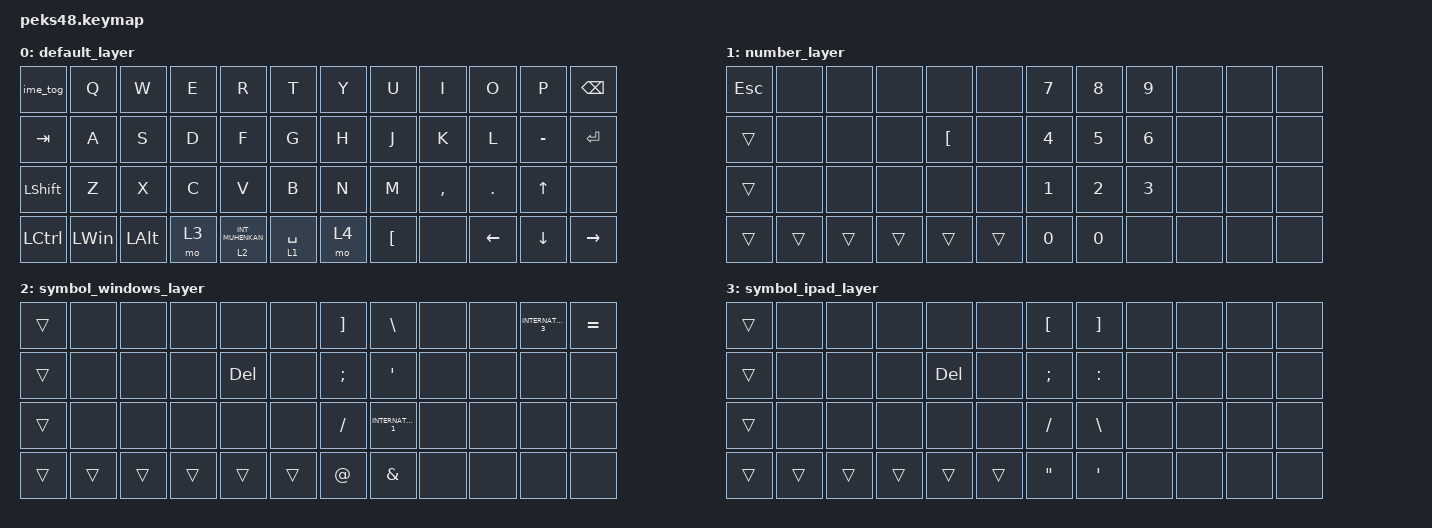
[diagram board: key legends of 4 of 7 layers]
#include <input/processors.dtsi>
#include <dt-bindings/zmk/input_transform.h>
#include <zephyr/dt-bindings/input/input-event-codes.h>
#include <behaviors.dtsi>
#include <dt-bindings/zmk/bt.h>
#include <dt-bindings/zmk/keys.h>
#include <dt-bindings/zmk/pointing.h>

// Conversion definition for using Japanese keyboard with OS settings

#define JP_DQUOTE       AT                // "
#define JP_AMPERSAND    CARET             // &
#define JP_QUOTE        AMPERSAND         // '
#define JP_EQUAL        UNDER             // =
#define JP_CARET        EQUAL             // ^
#define JP_YEN          0x89              // ¥
#define JP_PLUS         COLON             // +
#define JP_TILDE        PLUS              // ~
#define JP_PIPE         LS(0x89)          // |
#define JP_AT           LEFT_BRACKET      // @
#define JP_COLON        SINGLE_QUOTE      // :
#define JP_ASTERISK     DOUBLE_QUOTES     // *
#define JP_BACKQUOTE    LEFT_BRACE        // `
#define JP_UNDERSCORE   LS(0x87)          // _
#define JP_LBRACKET     RIGHT_BRACKET     // [
#define JP_RBRACKET     BACKSLASH         // ]
#define JP_LPAREN       ASTERISK          // (
#define JP_RPAREN       LEFT_PARENTHESIS  // )
#define JP_LBRACE       RIGHT_BRACE       // {
#define JP_RBRACE       PIPE              // }
#define JP_KANA         LANGUAGE_1        // かな
#define JP_EISU         LANGUAGE_2        // 英数
#define JP_HANZEN       GRAVE             // 半角/全角

&mt {
    flavor = "balanced";
    quick-tap-ms = <0>;
};

/ {
    macros {
        ime_tog: new_macro {
            compatible = "zmk,behavior-macro";
            #binding-cells = <0>;
            bindings =
                <&macro_press>,
                <&kp LALT>,
                <&macro_tap>,
                <&kp GRAVE>,
                <&macro_release>,
                <&kp LALT>;

            label = "NEW_MACRO";
        };
    };

    keymap {
        compatible = "zmk,keymap";

        default_layer {
            bindings = <
&ime_tog    &kp Q         &kp W         &kp E  &kp R               &kp T          &kp Y  &kp U             &kp I      &kp O           &kp P           &kp BACKSPACE
&kp TAB     &kp A         &kp S         &kp D  &kp F               &kp G          &kp H  &kp J             &kp K      &kp L           &kp MINUS       &kp ENTER
&kp LSHIFT  &kp Z         &kp X         &kp C  &kp V               &kp B          &kp N  &kp M             &kp COMMA  &kp DOT         &kp UP_ARROW    &none
&kp LCTRL   &kp LEFT_WIN  &kp LEFT_ALT  &mo 3  &lt 2 INT_MUHENKAN  &lt 1 SPACE    &mo 4  &kp LEFT_BRACKET  &none      &kp LEFT_ARROW  &kp DOWN_ARROW  &kp RIGHT_ARROW
            >;
        };

        number_layer {
            bindings = <
&kp ESCAPE  &none   &none   &none   &none             &none     &kp NUMBER_7  &kp NUMBER_8  &kp NUMBER_9  &none  &none  &none
&trans      &none   &none   &none   &kp LEFT_BRACKET  &none     &kp NUMBER_4  &kp NUMBER_5  &kp NUMBER_6  &none  &none  &none
&trans      &none   &none   &none   &none             &none     &kp NUMBER_1  &kp NUMBER_2  &kp NUMBER_3  &none  &none  &none
&trans      &trans  &trans  &trans  &trans            &trans    &kp NUMBER_0  &kp NUMBER_0  &none         &none  &none  &none
            >;
        };

        symbol_windows_layer {
            bindings = <
&trans  &none   &none   &none   &none       &none     &kp RIGHT_BRACKET  &kp BACKSLASH        &none  &none  &kp INTERNATIONAL_3  &kp EQUAL
&trans  &none   &none   &none   &kp DELETE  &none     &kp SEMICOLON      &kp SINGLE_QUOTE     &none  &none  &none                &none
&trans  &none   &none   &none   &none       &none     &kp SLASH          &kp INTERNATIONAL_1  &none  &none  &none                &none
&trans  &trans  &trans  &trans  &trans      &trans    &kp AT             &kp AMPERSAND        &none  &none  &none                &none
            >;
        };

        symbol_ipad_layer {
            bindings = <
&trans  &none   &none   &none   &none       &none     &kp LEFT_BRACKET   &kp RIGHT_BRACKET  &none  &none  &none  &none
&trans  &none   &none   &none   &kp DELETE  &none     &kp SEMICOLON      &kp COLON          &none  &none  &none  &none
&trans  &none   &none   &none   &none       &none     &kp SLASH          &kp BACKSLASH      &none  &none  &none  &none
&trans  &trans  &trans  &trans  &trans      &trans    &kp DOUBLE_QUOTES  &kp SINGLE_QUOTE   &none  &none  &none  &none
            >;
        };

        bt_fn_layer {
            bindings = <
&none        &bt BT_SEL 0  &bt BT_SEL 1  &bt BT_SEL 2  &bt BT_SEL 3  &bt BT_SEL 4    &kp F7  &kp F8  &kp F9  &kp F10  &kp F11  &bootloader
&none        &none         &none         &none         &none         &none           &kp F4  &kp F5  &kp F6  &none    &none    &none
&none        &none         &none         &none         &none         &none           &kp F1  &kp F2  &kp F3  &none    &none    &none
&bootloader  &none         &none         &none
            >;
        };

        layer_5 {
            bindings = <
&trans  &trans  &trans    &trans    &trans    &trans    &trans  &trans    &trans    &trans    &trans  &trans
&trans  &trans  &mkp MB3  &mkp MB2  &mkp MB1  &trans    &trans  &mkp MB1  &mkp MB2  &mkp MB3  &trans  &trans
&trans  &trans  &trans    &trans    &trans    &trans    &trans  &trans    &trans    &trans    &trans  &trans
&trans  &trans  &trans    &trans
            >;
        };

        layer_6 {
            bindings = <
&trans  &trans  &trans  &trans  &trans  &trans    &trans  &trans  &trans    &trans    &trans    &trans
&trans  &trans  &trans  &trans  &trans  &trans    &trans  &trans  &mkp MB1  &mkp MB3  &mkp MB2  &trans
&trans  &trans  &trans  &trans  &trans  &trans    &trans  &trans  &trans    &trans    &trans    &trans
&trans  &trans  &trans  &trans
            >;
        };
    };
};
